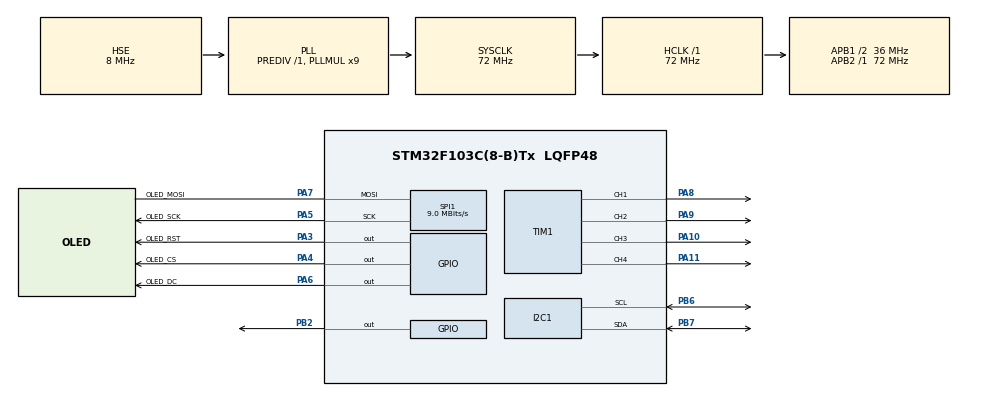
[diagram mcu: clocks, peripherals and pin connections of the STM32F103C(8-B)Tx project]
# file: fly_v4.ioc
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Dma.I2C1_RX.1.Direction=DMA_PERIPH_TO_MEMORY
Dma.I2C1_RX.1.Instance=DMA1_Channel7
Dma.I2C1_RX.1.MemDataAlignment=DMA_MDATAALIGN_BYTE
Dma.I2C1_RX.1.MemInc=DMA_MINC_ENABLE
Dma.I2C1_RX.1.Mode=DMA_NORMAL
Dma.I2C1_RX.1.PeriphDataAlignment=DMA_PDATAALIGN_BYTE
Dma.I2C1_RX.1.PeriphInc=DMA_PINC_DISABLE
Dma.I2C1_RX.1.Priority=DMA_PRIORITY_VERY_HIGH
Dma.Request0=SPI1_TX
Dma.Request1=I2C1_RX
Dma.SPI1_TX.0.Direction=DMA_MEMORY_TO_PERIPH
Dma.SPI1_TX.0.Instance=DMA1_Channel3
Dma.SPI1_TX.0.MemDataAlignment=DMA_MDATAALIGN_BYTE
Dma.SPI1_TX.0.MemInc=DMA_MINC_ENABLE
Dma.SPI1_TX.0.Mode=DMA_NORMAL
Dma.SPI1_TX.0.PeriphDataAlignment=DMA_PDATAALIGN_BYTE
Dma.SPI1_TX.0.PeriphInc=DMA_PINC_DISABLE
Dma.SPI1_TX.0.Priority=DMA_PRIORITY_MEDIUM
FREERTOS.HEAP_NUMBER=4
FREERTOS.Tasks01=defaultTask,24,128,StartDefaultTask,Default,NULL,Dynamic,NULL,NULL
FREERTOS.configGENERATE_RUN_TIME_STATS=1
FREERTOS.configLIBRARY_MAX_SYSCALL_INTERRUPT_PRIORITY=1
FREERTOS.configRECORD_STACK_HIGH_ADDRESS=1
FREERTOS.configTOTAL_HEAP_SIZE=4096*3
FREERTOS.configUSE_NEWLIB_REENTRANT=1
FREERTOS.configUSE_STATS_FORMATTING_FUNCTIONS=1
Mcu.Family=STM32F1
Mcu.Name=STM32F103C(8-B)Tx
Mcu.Package=LQFP48
NVIC.DMA1_Channel3_IRQn=true\:6\:0\:true\:false\:true\:true\:false\:true\:true
NVIC.DMA1_Channel7_IRQn=true\:5\:0\:true\:false\:true\:true\:false\:true\:true
NVIC.PriorityGroup=NVIC_PRIORITYGROUP_4
NVIC.SPI1_IRQn=true\:6\:0\:true\:false\:true\:true\:true\:true\:true
NVIC.TIM3_IRQn=true\:15\:0\:true\:false\:true\:true\:true\:true\:true
NVIC.TIM4_IRQn=true\:15\:0\:true\:false\:true\:false\:false\:true\:true
NVIC.TimeBase=TIM4_IRQn
NVIC.TimeBaseIP=TIM4
PA10.Signal=S_TIM1_CH3
PA11.Signal=S_TIM1_CH4
PA3.GPIO_Label=OLED_RST
PA3.Signal=GPIO_Output
PA4.GPIO_Label=OLED_CS
PA4.Signal=GPIO_Output
PA5.GPIO_Label=OLED_SCK
PA5.Mode=Simplex_Bidirectional_Master
PA5.Signal=SPI1_SCK
PA6.GPIO_Label=OLED_DC
PA6.Signal=GPIO_Output
PA7.GPIO_Label=OLED_MOSI
PA7.Mode=Simplex_Bidirectional_Master
PA7.Signal=SPI1_MOSI
PA8.Signal=S_TIM1_CH1
PA9.Signal=S_TIM1_CH2
PB2.Signal=GPIO_Output
PB6.Mode=I2C
PB6.Signal=I2C1_SCL
PB7.Mode=I2C
PB7.Signal=I2C1_SDA
PD0-OSC_IN.Mode=HSE-External-Oscillator
PD0-OSC_IN.Signal=RCC_OSC_IN
PD1-OSC_OUT.Mode=HSE-External-Oscillator
PD1-OSC_OUT.Signal=RCC_OSC_OUT
ProjectManager.HeapSize=0x200
ProjectManager.StackSize=0x400
ProjectManager.TargetToolchain=STM32CubeIDE
RCC.AHBFreq_Value=72000000
RCC.APB1CLKDivider=RCC_HCLK_DIV2
RCC.APB1Freq_Value=36000000
RCC.APB1TimFreq_Value=72000000
RCC.APB2Freq_Value=72000000
RCC.APB2TimFreq_Value=72000000
RCC.HCLKFreq_Value=72000000
RCC.PLLMUL=RCC_PLL_MUL9
RCC.PLLSourceVirtual=RCC_PLLSOURCE_HSE
RCC.SYSCLKFreq_VALUE=72000000
RCC.SYSCLKSource=RCC_SYSCLKSOURCE_PLLCLK
RCC.USBFreq_Value=72000000
SH.S_TIM1_CH1.0=TIM1_CH1,PWM Generation1 CH1
SH.S_TIM1_CH2.0=TIM1_CH2,PWM Generation2 CH2
SH.S_TIM1_CH3.0=TIM1_CH3,PWM Generation3 CH3
SH.S_TIM1_CH4.0=TIM1_CH4,PWM Generation4 CH4
SPI1.BaudRatePrescaler=SPI_BAUDRATEPRESCALER_8
SPI1.CLKPhase=SPI_PHASE_2EDGE
SPI1.CLKPolarity=SPI_POLARITY_HIGH
SPI1.CalculateBaudRate=9.0 MBits/s
SPI1.DataSize=SPI_DATASIZE_8BIT
SPI1.Direction=SPI_DIRECTION_1LINE
SPI1.Mode=SPI_MODE_MASTER
SPI1.VirtualType=VM_MASTER
TIM1.Channel-PWM\ Generation1\ CH1=TIM_CHANNEL_1
TIM1.Channel-PWM\ Generation2\ CH2=TIM_CHANNEL_2
TIM1.Channel-PWM\ Generation3\ CH3=TIM_CHANNEL_3
TIM1.Channel-PWM\ Generation4\ CH4=TIM_CHANNEL_4
TIM3.AutoReloadPreload=TIM_AUTORELOAD_PRELOAD_ENABLE
TIM3.Period=49
TIM3.Prescaler=71
VP_FREERTOS_VS_CMSIS_V2.Mode=CMSIS_V2
VP_SYS_VS_ND.Mode=No_Debug
VP_SYS_VS_tim4.Mode=TIM4
VP_TIM1_VS_ClockSourceINT.Mode=Internal
VP_TIM3_VS_ClockSourceINT.Mode=Internal
board=custom

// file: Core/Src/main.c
/* USER CODE BEGIN Header */
/**
  ******************************************************************************
  * @file           : main.c
  * @brief          : Main program body
  ******************************************************************************
  * @attention
  *
  * Copyright (c) 2022 STMicroelectronics.
  * All rights reserved.
  *
  * This software is licensed under terms that can be found in the LICENSE file
  * in the root directory of this software component.
  * If no LICENSE file comes with this software, it is provided AS-IS.
  *
  ******************************************************************************
  */
/* USER CODE END Header */
#include "main.h"
#include "cmsis_os.h"
#include "dma.h"
#include "i2c.h"
#include "spi.h"
#include "tim.h"
#include "gpio.h"

void SystemClock_Config(void);
void MX_FREERTOS_Init(void);

int main(void)
{

  /* MCU Configuration--------------------------------------------------------*/

  /* Reset of all peripherals, Initializes the Flash interface and the Systick. */
  HAL_Init();

  /* Configure the system clock */
  SystemClock_Config();

  /* Initialize all configured peripherals */
  MX_GPIO_Init();
  MX_DMA_Init();
  MX_I2C1_Init();
  MX_SPI1_Init();
  MX_TIM3_Init();
  MX_TIM1_Init();

  /* Init scheduler */
  osKernelInitialize();  /* Call init function for freertos objects (in freertos.c) */
  MX_FREERTOS_Init();

  /* Start scheduler */
  osKernelStart();

  /* We should never get here as control is now taken by the scheduler */
  /* Infinite loop */
    while (1) {

    /* USER CODE BEGIN 3 */
        HAL_GPIO_TogglePin(GPIOB,GPIO_PIN_2);
        HAL_Delay(500);

    }
  /* USER CODE END 3 */
}

void SystemClock_Config(void)
{
  RCC_OscInitTypeDef RCC_OscInitStruct = {0};
  RCC_ClkInitTypeDef RCC_ClkInitStruct = {0};

  /** Initializes the RCC Oscillators according to the specified parameters
  * in the RCC_OscInitTypeDef structure.
  */
  RCC_OscInitStruct.OscillatorType = RCC_OSCILLATORTYPE_HSE;
  RCC_OscInitStruct.HSEState = RCC_HSE_ON;
  RCC_OscInitStruct.HSEPredivValue = RCC_HSE_PREDIV_DIV1;
  RCC_OscInitStruct.HSIState = RCC_HSI_ON;
  RCC_OscInitStruct.PLL.PLLState = RCC_PLL_ON;
  RCC_OscInitStruct.PLL.PLLSource = RCC_PLLSOURCE_HSE;
  RCC_OscInitStruct.PLL.PLLMUL = RCC_PLL_MUL9;
  if (HAL_RCC_OscConfig(&RCC_OscInitStruct) != HAL_OK)
  {
    Error_Handler();
  }

  /** Initializes the CPU, AHB and APB buses clocks
  */
  RCC_ClkInitStruct.ClockType = RCC_CLOCKTYPE_HCLK|RCC_CLOCKTYPE_SYSCLK
                              |RCC_CLOCKTYPE_PCLK1|RCC_CLOCKTYPE_PCLK2;
  RCC_ClkInitStruct.SYSCLKSource = RCC_SYSCLKSOURCE_PLLCLK;
  RCC_ClkInitStruct.AHBCLKDivider = RCC_SYSCLK_DIV1;
  RCC_ClkInitStruct.APB1CLKDivider = RCC_HCLK_DIV2;
  RCC_ClkInitStruct.APB2CLKDivider = RCC_HCLK_DIV1;

  if (HAL_RCC_ClockConfig(&RCC_ClkInitStruct, FLASH_LATENCY_2) != HAL_OK)
  {
    Error_Handler();
  }
}

void HAL_TIM_PeriodElapsedCallback(TIM_HandleTypeDef *htim)
{
  if (htim->Instance == TIM4) {
    HAL_IncTick();
  }
}

void Error_Handler(void)
{
    __disable_irq();
    while (1) {
    }
}

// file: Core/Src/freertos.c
/* USER CODE BEGIN Header */
/**
  ******************************************************************************
  * File Name          : freertos.c
  * Description        : Code for freertos applications
  ******************************************************************************
  * @attention
  *
  * Copyright (c) 2022 STMicroelectronics.
  * All rights reserved.
  *
  * This software is licensed under terms that can be found in the LICENSE file
  * in the root directory of this software component.
  * If no LICENSE file comes with this software, it is provided AS-IS.
  *
  ******************************************************************************
  */
/* USER CODE END Header */

#include "FreeRTOS.h"
#include "task.h"
#include "main.h"
#include "cmsis_os.h"

/* USER CODE BEGIN Includes */
#include "blink_task.h"
#include "display_task.h"
#include "attitude_task.h"
#include "cpu_statics.h"
/* USER CODE END Includes */

/* Definitions for defaultTask */
osThreadId_t defaultTaskHandle;
const osThreadAttr_t defaultTask_attributes = {
  .name = "defaultTask",
  .stack_size = 128 * 4,
  .priority = (osPriority_t) osPriorityNormal,
};

void StartDefaultTask(void *argument);

void MX_FREERTOS_Init(void); /* (MISRA C 2004 rule 8.1) */

/* Hook prototypes */
void configureTimerForRunTimeStats(void);
unsigned long getRunTimeCounterValue(void);

/* USER CODE BEGIN 1 */
/* Functions needed when configGENERATE_RUN_TIME_STATS is on */
__weak void configureTimerForRunTimeStats(void)
{
    cpu_time = 0UL;
}

__weak unsigned long getRunTimeCounterValue(void)
{
return 0;
}

/* USER CODE END 1 */

void MX_FREERTOS_Init(void) {

  /* Create the thread(s) */
  /* creation of defaultTask */
  defaultTaskHandle = osThreadNew(StartDefaultTask, NULL, &defaultTask_attributes);

  /* USER CODE BEGIN RTOS_THREADS */
    /* add threads, ... */
    ledBlinkTaskCreate();
    displayTaskCreate();
    mpu6050TaskCreate();
    attitudeTaskCreate();
    cpuInfoTaskCreate();
  /* USER CODE END RTOS_THREADS */

}

void StartDefaultTask(void *argument)
{
    for (;;) {
        osDelay(1);
    }
}
